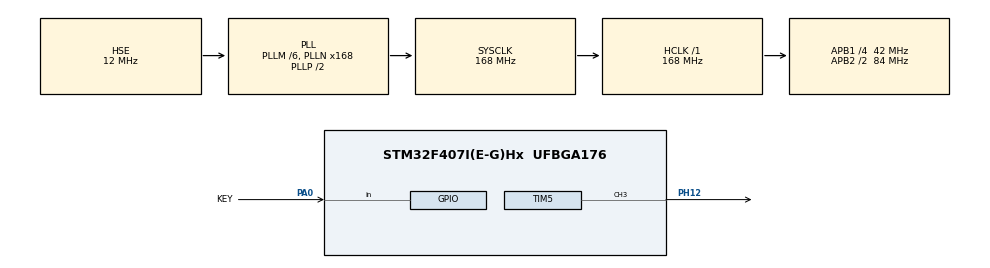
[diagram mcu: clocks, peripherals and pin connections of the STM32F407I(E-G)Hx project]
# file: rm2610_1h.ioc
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IWDG.Prescaler=IWDG_PRESCALER_16
IWDG.Reload=3999
Mcu.Family=STM32F4
Mcu.Name=STM32F407I(E-G)Hx
Mcu.Package=UFBGA176
NVIC.PriorityGroup=NVIC_PRIORITYGROUP_4
PA0-WKUP.GPIO_Label=KEY
PA0-WKUP.GPIO_PuPd=GPIO_PULLUP
PA0-WKUP.Signal=GPIO_Input
PA13.Mode=Serial_Wire
PA13.Signal=SYS_JTMS-SWDIO
PA14.Mode=Serial_Wire
PA14.Signal=SYS_JTCK-SWCLK
PH0-OSC_IN.Mode=HSE-External-Oscillator
PH0-OSC_IN.Signal=RCC_OSC_IN
PH1-OSC_OUT.Mode=HSE-External-Oscillator
PH1-OSC_OUT.Signal=RCC_OSC_OUT
PH12.Signal=S_TIM5_CH3
ProjectManager.HeapSize=0x200
ProjectManager.StackSize=0x400
ProjectManager.TargetToolchain=CMake
RCC.48MHZClocksFreq_Value=84000000
RCC.AHBFreq_Value=168000000
RCC.APB1CLKDivider=RCC_HCLK_DIV4
RCC.APB1Freq_Value=42000000
RCC.APB1TimFreq_Value=84000000
RCC.APB2CLKDivider=RCC_HCLK_DIV2
RCC.APB2Freq_Value=84000000
RCC.APB2TimFreq_Value=168000000
RCC.CortexFreq_Value=168000000
RCC.HCLKFreq_Value=168000000
RCC.HSE_VALUE=12000000
RCC.HSI_VALUE=16000000
RCC.LSE_VALUE=32768
RCC.PLLM=6
RCC.PLLN=168
RCC.PLLSourceVirtual=RCC_PLLSOURCE_HSE
RCC.SYSCLKFreq_VALUE=168000000
RCC.SYSCLKSource=RCC_SYSCLKSOURCE_PLLCLK
RCC.VCOOutputFreq_Value=336000000
SH.S_TIM5_CH3.0=TIM5_CH3,PWM Generation3 CH3
TIM1.Period=19999
TIM1.Prescaler=16799
TIM5.Channel-PWM\ Generation3\ CH3=TIM_CHANNEL_3
TIM5.OCMode_PWM-PWM\ Generation3\ CH3=TIM_OCMODE_PWM1
TIM5.Period=9999
TIM5.Prescaler=16799
TIM5.Pulse-PWM\ Generation3\ CH3=4999
VP_IWDG_VS_IWDG.Mode=IWDG_Activate
VP_TIM1_VS_ClockSourceINT.Mode=Internal
VP_TIM5_VS_ClockSourceINT.Mode=Internal
board=custom

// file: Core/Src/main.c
/* USER CODE BEGIN Header */
/**
  ******************************************************************************
  * @file           : main.c
  * @brief          : Main program body
  ******************************************************************************
  * @attention
  *
  * Copyright (c) 2026 STMicroelectronics.
  * All rights reserved.
  *
  * This software is licensed under terms that can be found in the LICENSE file
  * in the root directory of this software component.
  * If no LICENSE file comes with this software, it is provided AS-IS.
  *
  ******************************************************************************
  */
/* USER CODE END Header */
#include "main.h"
#include "iwdg.h"
#include "tim.h"
#include "gpio.h"

/* USER CODE BEGIN PV */

int gMode = 0;
int gAllowToggle = 1;
uint32_t gLastPress = 0;

/* USER CODE END PV */

void SystemClock_Config(void);

int main(void)
{

  /* MCU Configuration--------------------------------------------------------*/

  /* Reset of all peripherals, Initializes the Flash interface and the Systick. */
  HAL_Init();

  /* Configure the system clock */
  SystemClock_Config();

  /* Initialize all configured peripherals */
  MX_GPIO_Init();
  MX_TIM5_Init();
  MX_TIM1_Init();
  MX_IWDG_Init();
  /* USER CODE BEGIN 2 */

  HAL_TIM_Base_Start(&htim1);
  HAL_TIM_PWM_Start(&htim5, TIM_CHANNEL_3);
  HAL_IWDG_Init(&hiwdg);

  /* USER CODE END 2 */

  /* Infinite loop */
  /* USER CODE BEGIN WHILE */
  while (1)
  {
    HAL_IWDG_Refresh(&hiwdg);

    if (HAL_GPIO_ReadPin(KEY_GPIO_Port, KEY_Pin) == GPIO_PIN_RESET && gAllowToggle && HAL_GetTick() - gLastPress > 250)
    {
      gMode = (gMode + 1) % 3;
      gAllowToggle = 0;
      gLastPress = HAL_GetTick();
      htim5.Instance->CNT = 0;
    }
    if (HAL_GPIO_ReadPin(KEY_GPIO_Port, KEY_Pin) == GPIO_PIN_SET)
    {
      gAllowToggle = 1;
    }

    if (gMode == 0)
    {
      __HAL_TIM_SET_AUTORELOAD(&htim5, 99);
      __HAL_TIM_SET_COMPARE(&htim5, TIM_CHANNEL_3, 0);
    }
    else if (gMode == 1)
    {
      __HAL_TIM_SET_AUTORELOAD(&htim5, 99);
      uint32_t aCNT = htim1.Instance->CNT / 100;
      __HAL_TIM_SET_COMPARE(&htim5, TIM_CHANNEL_3,
        (aCNT < 100) ? (aCNT) : (200 - aCNT));
    }
    else if (gMode == 2)
    {
      __HAL_TIM_SET_AUTORELOAD(&htim5, 9999);
      __HAL_TIM_SET_COMPARE(&htim5, TIM_CHANNEL_3, 4999);
    }
    /* USER CODE END WHILE */

  }
}

void SystemClock_Config(void)
{
  RCC_OscInitTypeDef RCC_OscInitStruct = {0};
  RCC_ClkInitTypeDef RCC_ClkInitStruct = {0};

  /** Configure the main internal regulator output voltage
  */
  __HAL_RCC_PWR_CLK_ENABLE();
  __HAL_PWR_VOLTAGESCALING_CONFIG(PWR_REGULATOR_VOLTAGE_SCALE1);

  /** Initializes the RCC Oscillators according to the specified parameters
  * in the RCC_OscInitTypeDef structure.
  */
  RCC_OscInitStruct.OscillatorType = RCC_OSCILLATORTYPE_LSI|RCC_OSCILLATORTYPE_HSE;
  RCC_OscInitStruct.HSEState = RCC_HSE_ON;
  RCC_OscInitStruct.LSIState = RCC_LSI_ON;
  RCC_OscInitStruct.PLL.PLLState = RCC_PLL_ON;
  RCC_OscInitStruct.PLL.PLLSource = RCC_PLLSOURCE_HSE;
  RCC_OscInitStruct.PLL.PLLM = 6;
  RCC_OscInitStruct.PLL.PLLN = 168;
  RCC_OscInitStruct.PLL.PLLP = RCC_PLLP_DIV2;
  RCC_OscInitStruct.PLL.PLLQ = 4;
  if (HAL_RCC_OscConfig(&RCC_OscInitStruct) != HAL_OK)
  {
    Error_Handler();
  }

  /** Initializes the CPU, AHB and APB buses clocks
  */
  RCC_ClkInitStruct.ClockType = RCC_CLOCKTYPE_HCLK|RCC_CLOCKTYPE_SYSCLK
                              |RCC_CLOCKTYPE_PCLK1|RCC_CLOCKTYPE_PCLK2;
  RCC_ClkInitStruct.SYSCLKSource = RCC_SYSCLKSOURCE_PLLCLK;
  RCC_ClkInitStruct.AHBCLKDivider = RCC_SYSCLK_DIV1;
  RCC_ClkInitStruct.APB1CLKDivider = RCC_HCLK_DIV4;
  RCC_ClkInitStruct.APB2CLKDivider = RCC_HCLK_DIV2;

  if (HAL_RCC_ClockConfig(&RCC_ClkInitStruct, FLASH_LATENCY_5) != HAL_OK)
  {
    Error_Handler();
  }
}

/* USER CODE BEGIN 4 */

// void HAL_GPIO_EXTI_Callback(uint16_t GPIO_Pin)
// {
//   if (GPIO_Pin == GPIO_PIN_0)
//   {
//     gMode = (gMode + 1) % 3;
//   }
// }

/* USER CODE END 4 */

void Error_Handler(void)
{
  __disable_irq();
  while (1)
  {
  }
}
